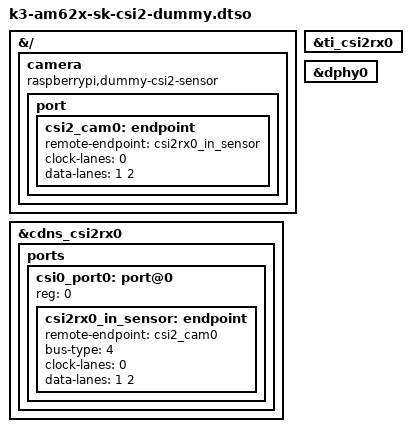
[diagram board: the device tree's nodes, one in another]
// SPDX-License-Identifier: GPL-2.0
/*
 * Dummy sensor for always on non-programmable sources
 * Copyright (C) 2024 Texas Instruments Incorporated - https://www.ti.com/
 */

/dts-v1/;
/plugin/;

#include <dt-bindings/gpio/gpio.h>

&{/} {
	camera {
		compatible = "raspberrypi,dummy-csi2-sensor";

		port {
			csi2_cam0: endpoint {
				remote-endpoint = <&csi2rx0_in_sensor>;
				clock-lanes = <0>;
				data-lanes = <1 2>;
			};
		};
	};
};

&cdns_csi2rx0 {
	ports {
		#address-cells = <1>;
		#size-cells = <0>;

		csi0_port0: port@0 {
			reg = <0>;
			status = "okay";

			csi2rx0_in_sensor: endpoint {
				remote-endpoint = <&csi2_cam0>;
				bus-type = <4>; /* CSI2 DPHY. */
				clock-lanes = <0>;
				data-lanes = <1 2>;
			};
		};
	};
};

&ti_csi2rx0 {
	status = "okay";
};

&dphy0 {
	status = "okay";
};
